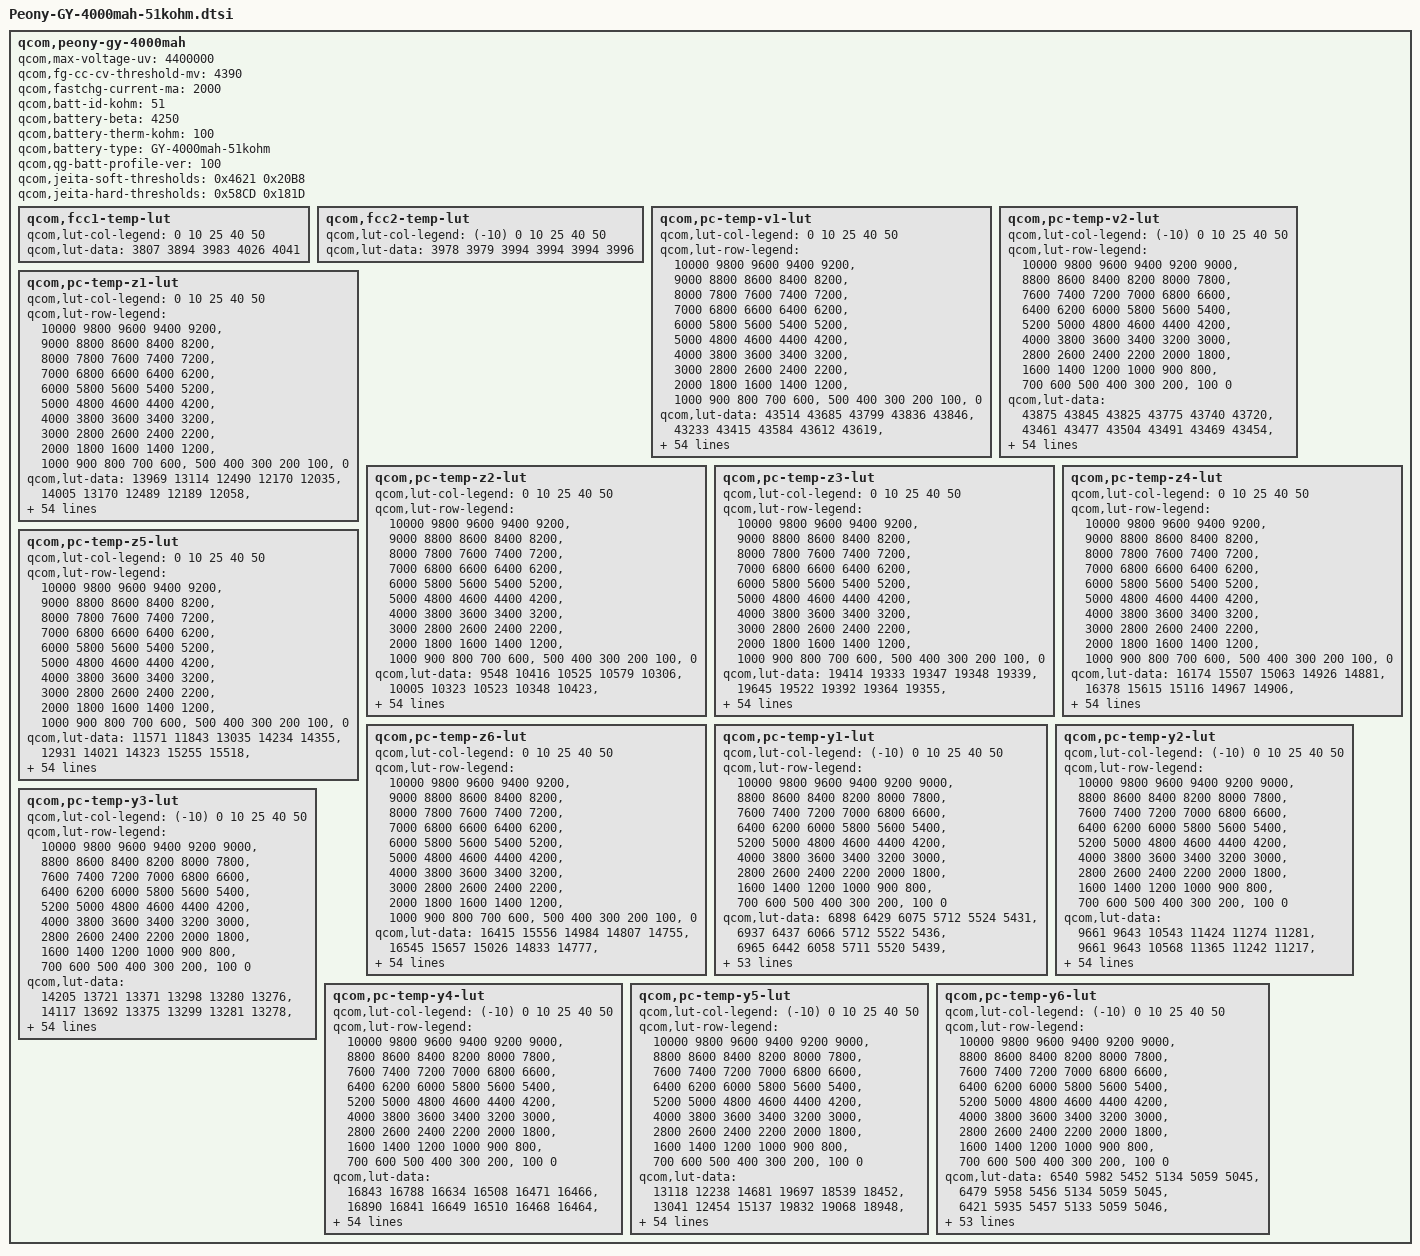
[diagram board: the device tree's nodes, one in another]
/* Copyright (c) 2018, The Linux Foundation. All rights reserved.
 * Copyright (C) 2021 XiaoMi, Inc.
 *
 * This program is free software; you can redistribute it and/or modify
 * it under the terms of the GNU General Public License version 2 and
 * only version 2 as published by the Free Software Foundation.
 *
 * This program is distributed in the hope that it will be useful,
 * but WITHOUT ANY WARRANTY; without even the implied warranty of
 * MERCHANTABILITY or FITNESS FOR A PARTICULAR PURPOSE.  See the
 * GNU General Public License for more details.
 */

qcom,peony-gy-4000mah {
	/* Peony-GY-4000mah-51kohm_Master_2018.12.27 */
	qcom,max-voltage-uv = <4400000>;
	qcom,fg-cc-cv-threshold-mv = <4390>;
	qcom,fastchg-current-ma = <2000>;
	qcom,batt-id-kohm = <51>;
	qcom,battery-beta = <4250>;
	qcom,battery-therm-kohm = <100>;
	qcom,battery-type =
		"GY-4000mah-51kohm";
	qcom,qg-batt-profile-ver = <100>;

/*	qcom,jeita-fcc-ranges = <0   50   400000
				 51  100  1200000
				 101 150  1950000
				 151 450  2000000
				 451 550  1000000
				 551 600  0>;
	qcom,jeita-fv-ranges =  <0   50   4400000
				 51  100  4400000
				 101 150  4400000
				 151 450  4400000
				 451 550  4100000
				 551 600  4100000>;*/

	/* COOL = 15 DegC, WARM = 45 DegC */
	qcom,jeita-soft-thresholds = <0x4621 0x20B8>;
	/* COLD = 0 DegC, HOT = 55 DegC */
	qcom,jeita-hard-thresholds = <0x58CD 0x181D>;

	qcom,fcc1-temp-lut {
		qcom,lut-col-legend = <0 10 25 40 50>;
		qcom,lut-data = <3807 3894 3983 4026 4041>;
	};

	qcom,fcc2-temp-lut {
		qcom,lut-col-legend = <(-10) 0 10 25 40 50>;
		qcom,lut-data = <3978 3979 3994 3994 3994 3996>;
	};

	qcom,pc-temp-v1-lut {
		qcom,lut-col-legend = <0 10 25 40 50>;
		qcom,lut-row-legend = <10000 9800 9600 9400 9200>,
			<9000 8800 8600 8400 8200>,
			<8000 7800 7600 7400 7200>,
			<7000 6800 6600 6400 6200>,
			<6000 5800 5600 5400 5200>,
			<5000 4800 4600 4400 4200>,
			<4000 3800 3600 3400 3200>,
			<3000 2800 2600 2400 2200>,
			<2000 1800 1600 1400 1200>,
			<1000 900 800 700 600>,
			<500 400 300 200 100>,
			<0>;
		qcom,lut-data = <43514 43685 43799 43836 43846>,
			<43233 43415 43584 43612 43619>,
			<42976 43161 43332 43381 43391>,
			<42734 42918 43090 43147 43163>,
			<42501 42681 42854 42912 42930>,
			<42277 42447 42616 42675 42695>,
			<42060 42219 42376 42440 42462>,
			<41851 41999 42138 42206 42229>,
			<41649 41786 41909 41975 41998>,
			<41457 41578 41685 41746 41768>,
			<41269 41379 41467 41519 41540>,
			<41072 41186 41258 41299 41317>,
			<40859 40986 41056 41083 41096>,
			<40631 40779 40856 40875 40884>,
			<40375 40558 40650 40670 40680>,
			<40104 40305 40440 40472 40484>,
			<39898 40050 40223 40280 40294>,
			<39765 39873 40022 40096 40111>,
			<39656 39757 39862 39922 39935>,
			<39542 39649 39733 39766 39776>,
			<39428 39520 39579 39601 39611>,
			<39314 39377 39353 39375 39398>,
			<39197 39218 39108 39108 39138>,
			<39079 39017 38920 38915 38936>,
			<38965 38819 38764 38785 38801>,
			<38853 38679 38644 38676 38689>,
			<38746 38567 38555 38573 38581>,
			<38645 38480 38483 38481 38482>,
			<38548 38412 38413 38395 38390>,
			<38465 38356 38347 38314 38299>,
			<38403 38309 38287 38241 38217>,
			<38351 38268 38230 38173 38148>,
			<38305 38232 38178 38112 38087>,
			<38262 38201 38131 38055 38028>,
			<38224 38174 38091 38006 37973>,
			<38190 38142 38050 37958 37918>,
			<38160 38109 38008 37908 37862>,
			<38123 38067 37961 37857 37804>,
			<38072 38003 37895 37790 37731>,
			<38004 37913 37804 37700 37635>,
			<37916 37812 37700 37597 37527>,
			<37794 37694 37589 37486 37415>,
			<37658 37559 37461 37359 37290>,
			<37504 37395 37301 37204 37130>,
			<37354 37265 37165 37072 37003>,
			<37249 37191 37080 36985 36926>,
			<37212 37154 37050 36959 36901>,
			<37180 37126 37035 36941 36881>,
			<37147 37099 37013 36919 36858>,
			<37076 37035 36948 36839 36768>,
			<36834 36772 36679 36544 36449>,
			<36384 36325 36241 36097 36002>,
			<35810 35750 35668 35517 35421>,
			<35030 34967 34890 34727 34627>,
			<33792 33731 33678 33490 33384>,
			<30000 30000 30000 30000 30000>;
	};

	qcom,pc-temp-v2-lut {
		qcom,lut-col-legend = <(-10) 0 10 25 40 50>;
		qcom,lut-row-legend = <10000 9800 9600 9400 9200 9000>,
			<8800 8600 8400 8200 8000 7800>,
			<7600 7400 7200 7000 6800 6600>,
			<6400 6200 6000 5800 5600 5400>,
			<5200 5000 4800 4600 4400 4200>,
			<4000 3800 3600 3400 3200 3000>,
			<2800 2600 2400 2200 2000 1800>,
			<1600 1400 1200 1000 900 800>,
			<700 600 500 400 300 200>,
			<100 0>;
		qcom,lut-data = <43875 43845 43825 43775 43740 43720>,
			<43461 43477 43504 43491 43469 43454>,
			<43087 43138 43205 43222 43207 43197>,
			<42758 42832 42929 42965 42957 42951>,
			<42469 42555 42676 42723 42719 42715>,
			<42203 42301 42431 42485 42484 42482>,
			<41947 42072 42183 42249 42249 42248>,
			<41710 41855 41941 42015 42016 42015>,
			<41492 41616 41716 41788 41786 41785>,
			<41283 41336 41505 41564 41559 41558>,
			<41114 41129 41301 41346 41336 41334>,
			<41015 41046 41111 41133 41118 41114>,
			<40930 40986 40922 40926 40903 40899>,
			<40726 40820 40702 40720 40696 40692>,
			<40165 40343 40443 40508 40494 40490>,
			<39661 39893 40190 40300 40299 40295>,
			<39455 39667 39961 40095 40113 40109>,
			<39309 39493 39742 39902 39933 39929>,
			<39149 39313 39537 39728 39760 39756>,
			<38974 39130 39346 39566 39595 39593>,
			<38810 38955 39162 39387 39417 39417>,
			<38661 38788 38972 39161 39187 39189>,
			<38526 38630 38789 38927 38944 38949>,
			<38415 38489 38633 38749 38761 38766>,
			<38325 38361 38497 38607 38620 38623>,
			<38245 38254 38372 38484 38497 38499>,
			<38173 38175 38250 38375 38387 38387>,
			<38108 38111 38139 38277 38288 38287>,
			<38048 38055 38057 38187 38199 38196>,
			<37993 38005 37995 38105 38118 38112>,
			<37939 37960 37943 38030 38045 38038>,
			<37885 37916 37897 37959 37979 37972>,
			<37832 37873 37856 37894 37919 37911>,
			<37776 37830 37815 37834 37852 37841>,
			<37720 37787 37776 37780 37779 37763>,
			<37661 37742 37734 37725 37699 37675>,
			<37597 37692 37688 37665 37609 37571>,
			<37530 37637 37636 37602 37515 37459>,
			<37464 37573 37575 37533 37431 37368>,
			<37401 37500 37503 37459 37357 37293>,
			<37338 37416 37421 37377 37280 37215>,
			<37274 37318 37323 37280 37185 37122>,
			<37208 37207 37209 37166 37075 37016>,
			<37135 37098 37083 37041 36951 36893>,
			<37052 37002 36959 36927 36854 36797>,
			<36947 36919 36872 36870 36808 36755>,
			<36885 36879 36837 36852 36795 36742>,
			<36806 36833 36805 36831 36776 36723>,
			<36705 36770 36759 36789 36734 36677>,
			<36550 36655 36646 36671 36589 36511>,
			<36309 36402 36381 36342 36215 36119>,
			<35914 35962 35915 35839 35693 35595>,
			<35338 35342 35275 35180 35017 34909>,
			<34487 34468 34383 34260 34073 33958>,
			<33097 33083 33023 32941 32737 32624>,
			<28238 27945 27843 28406 27873 27872>;
	};

	qcom,pc-temp-z1-lut {
		qcom,lut-col-legend = <0 10 25 40 50>;
		qcom,lut-row-legend = <10000 9800 9600 9400 9200>,
			<9000 8800 8600 8400 8200>,
			<8000 7800 7600 7400 7200>,
			<7000 6800 6600 6400 6200>,
			<6000 5800 5600 5400 5200>,
			<5000 4800 4600 4400 4200>,
			<4000 3800 3600 3400 3200>,
			<3000 2800 2600 2400 2200>,
			<2000 1800 1600 1400 1200>,
			<1000 900 800 700 600>,
			<500 400 300 200 100>,
			<0>;
		qcom,lut-data = <13969 13114 12490 12170 12035>,
			<14005 13170 12489 12189 12058>,
			<14014 13164 12500 12193 12066>,
			<14005 13147 12505 12192 12068>,
			<13985 13138 12508 12187 12066>,
			<13962 13137 12508 12180 12062>,
			<13943 13140 12502 12173 12060>,
			<13927 13142 12490 12165 12059>,
			<13921 13137 12484 12162 12058>,
			<13925 13129 12478 12164 12060>,
			<13929 13126 12477 12166 12063>,
			<13921 13121 12481 12168 12065>,
			<13899 13109 12484 12170 12066>,
			<13872 13080 12479 12170 12067>,
			<13837 13063 12463 12168 12068>,
			<13788 13060 12453 12167 12069>,
			<13757 13053 12453 12168 12071>,
			<13748 13049 12454 12170 12073>,
			<13745 13055 12459 12171 12075>,
			<13747 13065 12472 12174 12078>,
			<13752 13076 12481 12177 12081>,
			<13759 13090 12486 12179 12082>,
			<13767 13101 12491 12180 12083>,
			<13777 13110 12494 12181 12084>,
			<13784 13118 12497 12184 12087>,
			<13781 13118 12500 12187 12091>,
			<13773 13111 12505 12191 12094>,
			<13770 13107 12510 12196 12097>,
			<13770 13128 12513 12200 12101>,
			<13773 13154 12515 12204 12104>,
			<13796 13160 12517 12209 12109>,
			<13824 13157 12519 12215 12113>,
			<13831 13156 12522 12220 12118>,
			<13834 13169 12525 12226 12123>,
			<13840 13194 12531 12232 12128>,
			<13845 13206 12538 12238 12133>,
			<13854 13211 12547 12242 12138>,
			<13866 13214 12557 12246 12142>,
			<13894 13214 12568 12250 12146>,
			<13930 13213 12583 12254 12150>,
			<13947 13215 12593 12259 12154>,
			<13957 13238 12594 12268 12158>,
			<13957 13248 12592 12275 12162>,
			<13939 13242 12593 12275 12165>,
			<13939 13275 12611 12277 12168>,
			<13913 13273 12605 12288 12170>,
			<13906 13292 12610 12284 12171>,
			<13933 13270 12604 12289 12175>,
			<13964 13266 12601 12292 12179>,
			<13981 13267 12617 12300 12185>,
			<13972 13272 12626 12307 12192>,
			<13958 13311 12637 12320 12201>,
			<13966 13310 12665 12330 12214>,
			<13998 13369 12691 12349 12232>,
			<13998 13369 12691 12349 12232>,
			<13998 13369 12691 12349 12232>;
	};

	qcom,pc-temp-z2-lut {
		qcom,lut-col-legend = <0 10 25 40 50>;
		qcom,lut-row-legend = <10000 9800 9600 9400 9200>,
			<9000 8800 8600 8400 8200>,
			<8000 7800 7600 7400 7200>,
			<7000 6800 6600 6400 6200>,
			<6000 5800 5600 5400 5200>,
			<5000 4800 4600 4400 4200>,
			<4000 3800 3600 3400 3200>,
			<3000 2800 2600 2400 2200>,
			<2000 1800 1600 1400 1200>,
			<1000 900 800 700 600>,
			<500 400 300 200 100>,
			<0>;
		qcom,lut-data = <9548 10416 10525 10579 10306>,
			<10005 10323 10523 10348 10423>,
			<10156 10349 10543 10486 10486>,
			<10211 10352 10710 10558 10522>,
			<10228 10345 11014 10545 10498>,
			<10237 10319 11062 10519 10457>,
			<10240 10291 10740 10483 10429>,
			<10241 10276 10451 10428 10391>,
			<10239 10262 10414 10399 10366>,
			<10226 10252 10393 10394 10363>,
			<10202 10246 10385 10396 10365>,
			<10179 10242 10391 10394 10370>,
			<10157 10273 10404 10385 10384>,
			<10138 10385 10489 10382 10388>,
			<10122 10450 10692 10399 10341>,
			<10107 10384 10831 10418 10283>,
			<10098 10289 10908 10409 10281>,
			<10094 10281 10946 10379 10303>,
			<10092 10311 10850 10368 10329>,
			<10093 10345 10615 10397 10352>,
			<10106 10370 10541 10447 10382>,
			<10119 10392 10602 10541 10463>,
			<10120 10408 10667 10685 10628>,
			<10120 10421 10669 10721 10697>,
			<10121 10429 10625 10574 10609>,
			<10129 10433 10594 10438 10507>,
			<10141 10441 10599 10465 10516>,
			<10154 10449 10612 10544 10583>,
			<10171 10462 10614 10582 10615>,
			<10187 10474 10609 10598 10624>,
			<10201 10480 10606 10606 10614>,
			<10214 10483 10615 10596 10557>,
			<10229 10488 10628 10573 10473>,
			<10247 10495 10632 10559 10411>,
			<10262 10506 10634 10551 10362>,
			<10243 10518 10636 10547 10334>,
			<10141 10532 10650 10577 10361>,
			<10072 10549 10674 10639 10431>,
			<9992 10572 10705 10663 10485>,
			<9920 10599 10751 10670 10529>,
			<9931 10617 10774 10675 10555>,
			<9974 10625 10764 10699 10554>,
			<10016 10634 10754 10727 10553>,
			<10057 10651 10765 10701 10638>,
			<10194 10758 10817 10686 10622>,
			<10329 14680 10837 10625 10523>,
			<10361 15143 10842 10651 10529>,
			<10255 14898 10814 10642 10542>,
			<10229 15989 10836 10711 10586>,
			<10228 21524 10894 10782 10715>,
			<10052 14520 10903 10658 10433>,
			<9856 14190 10874 10463 10283>,
			<9735 13311 10767 10402 10217>,
			<9567 12542 10654 10309 10162>,
			<9567 12542 10654 10309 10162>,
			<9567 12542 10654 10309 10162>;
	};

	qcom,pc-temp-z3-lut {
		qcom,lut-col-legend = <0 10 25 40 50>;
		qcom,lut-row-legend = <10000 9800 9600 9400 9200>,
			<9000 8800 8600 8400 8200>,
			<8000 7800 7600 7400 7200>,
			<7000 6800 6600 6400 6200>,
			<6000 5800 5600 5400 5200>,
			<5000 4800 4600 4400 4200>,
			<4000 3800 3600 3400 3200>,
			<3000 2800 2600 2400 2200>,
			<2000 1800 1600 1400 1200>,
			<1000 900 800 700 600>,
			<500 400 300 200 100>,
			<0>;
		qcom,lut-data = <19414 19333 19347 19348 19339>,
			<19645 19522 19392 19364 19355>,
			<19720 19571 19441 19389 19374>,
			<19736 19596 19459 19403 19388>,
			<19728 19605 19467 19411 19396>,
			<19715 19607 19471 19416 19402>,
			<19705 19606 19474 19417 19404>,
			<19695 19603 19476 19417 19404>,
			<19688 19596 19476 19416 19404>,
			<19683 19589 19474 19413 19402>,
			<19680 19584 19470 19408 19398>,
			<19680 19581 19463 19403 19395>,
			<19687 19579 19455 19395 19392>,
			<19695 19577 19454 19390 19388>,
			<19701 19574 19454 19387 19381>,
			<19706 19564 19454 19384 19372>,
			<19707 19548 19451 19381 19368>,
			<19684 19533 19446 19378 19365>,
			<19648 19509 19436 19374 19362>,
			<19625 19488 19417 19368 19355>,
			<19609 19488 19410 19364 19349>,
			<19600 19496 19419 19368 19350>,
			<19604 19503 19430 19378 19358>,
			<19617 19515 19431 19381 19361>,
			<19627 19526 19425 19367 19349>,
			<19634 19526 19420 19355 19336>,
			<19639 19525 19417 19355 19339>,
			<19640 19524 19416 19359 19351>,
			<19640 19523 19416 19363 19364>,
			<19639 19520 19418 19374 19381>,
			<19633 19518 19419 19383 19393>,
			<19621 19514 19422 19386 19390>,
			<19610 19509 19425 19389 19382>,
			<19600 19504 19425 19389 19374>,
			<19588 19497 19423 19383 19366>,
			<19552 19491 19420 19377 19358>,
			<19465 19484 19416 19372 19352>,
			<19406 19479 19412 19367 19347>,
			<19344 19478 19410 19364 19346>,
			<19276 19477 19408 19361 19345>,
			<19265 19476 19405 19359 19346>,
			<19264 19470 19401 19359 19346>,
			<19263 19465 19398 19358 19348>,
			<19262 19462 19398 19359 19357>,
			<19261 19386 19391 19355 19355>,
			<19260 19259 19375 19348 19342>,
			<19260 19259 19378 19344 19334>,
			<19260 19259 19360 19337 19329>,
			<19261 19258 19351 19334 19321>,
			<19261 19256 19346 19330 19316>,
			<19261 19258 19342 19343 19351>,
			<19263 19258 19345 19357 19354>,
			<19264 19259 19352 19360 19355>,
			<19268 19259 19345 19358 19355>,
			<19268 19259 19345 19358 19355>,
			<19268 19259 19345 19358 19355>;
	};

	qcom,pc-temp-z4-lut {
		qcom,lut-col-legend = <0 10 25 40 50>;
		qcom,lut-row-legend = <10000 9800 9600 9400 9200>,
			<9000 8800 8600 8400 8200>,
			<8000 7800 7600 7400 7200>,
			<7000 6800 6600 6400 6200>,
			<6000 5800 5600 5400 5200>,
			<5000 4800 4600 4400 4200>,
			<4000 3800 3600 3400 3200>,
			<3000 2800 2600 2400 2200>,
			<2000 1800 1600 1400 1200>,
			<1000 900 800 700 600>,
			<500 400 300 200 100>,
			<0>;
		qcom,lut-data = <16174 15507 15063 14926 14881>,
			<16378 15615 15116 14967 14906>,
			<16245 15555 15100 14938 14889>,
			<16076 15373 15052 14905 14867>,
			<15884 15216 14959 14870 14842>,
			<15699 15117 14894 14835 14814>,
			<15559 15035 14857 14807 14791>,
			<15443 14971 14827 14784 14770>,
			<15346 14918 14797 14763 14753>,
			<15264 14876 14770 14744 14737>,
			<15192 14845 14752 14728 14723>,
			<15122 14817 14741 14722 14714>,
			<15052 14782 14731 14718 14708>,
			<15000 14739 14715 14713 14703>,
			<14975 14718 14694 14705 14700>,
			<14958 14733 14685 14698 14697>,
			<14939 14754 14681 14690 14693>,
			<14911 14757 14678 14683 14686>,
			<14882 14743 14675 14679 14681>,
			<14861 14729 14674 14676 14678>,
			<14846 14718 14678 14674 14676>,
			<14831 14707 14718 14704 14698>,
			<14811 14705 14776 14781 14770>,
			<14787 14742 14812 14816 14811>,
			<14771 14790 14838 14827 14821>,
			<14761 14805 14848 14832 14827>,
			<14755 14812 14836 14825 14818>,
			<14755 14814 14815 14804 14788>,
			<14758 14803 14796 14782 14759>,
			<14760 14786 14778 14757 14728>,
			<14758 14771 14761 14734 14705>,
			<14753 14756 14746 14716 14695>,
			<14749 14742 14733 14702 14689>,
			<14745 14729 14722 14696 14687>,
			<14741 14716 14712 14693 14686>,
			<14760 14707 14705 14691 14686>,
			<14836 14698 14701 14690 14686>,
			<14883 14693 14698 14690 14687>,
			<14938 14693 14699 14691 14689>,
			<15000 14692 14705 14701 14701>,
			<15005 14692 14708 14709 14710>,
			<14999 14691 14702 14703 14704>,
			<14991 14690 14695 14695 14695>,
			<14977 14687 14693 14695 14693>,
			<14910 14732 14678 14686 14684>,
			<14896 14835 14664 14667 14668>,
			<14889 14828 14652 14661 14664>,
			<14883 14822 14655 14649 14650>,
			<14876 14814 14653 14633 14636>,
			<14873 14811 14656 14637 14638>,
			<14881 14825 14684 14659 14650>,
			<14903 14841 14690 14655 14657>,
			<14917 14851 14688 14656 14661>,
			<14942 14865 14702 14664 14665>,
			<14942 14865 14702 14664 14665>,
			<14942 14865 14702 14664 14665>;
	};

	qcom,pc-temp-z5-lut {
		qcom,lut-col-legend = <0 10 25 40 50>;
		qcom,lut-row-legend = <10000 9800 9600 9400 9200>,
			<9000 8800 8600 8400 8200>,
			<8000 7800 7600 7400 7200>,
			<7000 6800 6600 6400 6200>,
			<6000 5800 5600 5400 5200>,
			<5000 4800 4600 4400 4200>,
			<4000 3800 3600 3400 3200>,
			<3000 2800 2600 2400 2200>,
			<2000 1800 1600 1400 1200>,
			<1000 900 800 700 600>,
			<500 400 300 200 100>,
			<0>;
		qcom,lut-data = <11571 11843 13035 14234 14355>,
			<12931 14021 14323 15255 15518>,
			<13612 15060 15919 16720 16930>,
			<14055 15749 16679 17786 18097>,
			<14381 16360 17143 18420 18880>,
			<14654 16910 17722 18944 19566>,
			<14936 17426 18846 19475 20211>,
			<15211 17967 20115 19976 20785>,
			<15491 18506 21199 20555 21401>,
			<15784 19149 22324 21524 22170>,
			<16119 20008 23283 22315 23059>,
			<16572 21163 23941 22291 24064>,
			<17248 23019 24668 21987 25269>,
			<18049 26039 26037 21874 25785>,
			<18958 27678 28941 22510 25056>,
			<20004 26882 31254 23503 24120>,
			<20467 25411 31654 24370 24402>,
			<19602 24500 30952 25283 25950>,
			<18245 22772 30110 26186 26923>,
			<17760 21243 29586 26989 26802>,
			<17655 22762 31061 28001 26431>,
			<17656 28695 39345 30446 26852>,
			<18498 35086 48510 34201 28650>,
			<20943 44649 47721 34841 29300>,
			<23732 52317 38698 27375 23766>,
			<26823 51972 31398 20057 17658>,
			<30047 48304 28196 18963 17170>,
			<33216 45025 26176 18473 17565>,
			<36728 42990 25852 18484 18455>,
			<38541 41332 26010 19954 22572>,
			<37615 40323 26423 22241 26812>,
			<35372 39431 28357 25359 28120>,
			<33282 38553 31470 29332 28908>,
			<31524 37490 34049 31774 29301>,
			<29583 36279 36504 33446 29383>,
			<26391 35429 38242 34270 29209>,
			<21145 34750 39361 34165 28866>,
			<17664 34388 40098 33798 28412>,
			<14699 35993 39974 33005 27733>,
			<11754 39483 38639 30407 26369>,
			<11342 40387 36783 27763 25089>,
			<11366 36415 33498 26033 24318>,
			<11389 34436 31186 24989 23870>,
			<11422 35750 31549 24944 27112>,
			<11717 26547 31969 24900 27387>,
			<11686 11837 27956 24072 22607>,
			<11638 11801 31341 23310 20529>,
			<11639 11786 23238 22816 21399>,
			<11638 11698 21003 26062 22631>,
			<11662 11719 19921 23230 20023>,
			<11715 11851 17379 20703 25333>,
			<11695 11735 16567 22350 22802>,
			<11591 11628 16970 21885 20933>,
			<11484 11502 15329 19253 18815>,
			<11484 11502 15329 19253 18815>,
			<11484 11502 15329 19253 18815>;
	};

	qcom,pc-temp-z6-lut {
		qcom,lut-col-legend = <0 10 25 40 50>;
		qcom,lut-row-legend = <10000 9800 9600 9400 9200>,
			<9000 8800 8600 8400 8200>,
			<8000 7800 7600 7400 7200>,
			<7000 6800 6600 6400 6200>,
			<6000 5800 5600 5400 5200>,
			<5000 4800 4600 4400 4200>,
			<4000 3800 3600 3400 3200>,
			<3000 2800 2600 2400 2200>,
			<2000 1800 1600 1400 1200>,
			<1000 900 800 700 600>,
			<500 400 300 200 100>,
			<0>;
		qcom,lut-data = <16415 15556 14984 14807 14755>,
			<16545 15657 15026 14833 14777>,
			<16471 15628 15034 14832 14780>,
			<16372 15535 15021 14827 14778>,
			<16244 15449 14981 14815 14772>,
			<16117 15387 14947 14800 14763>,
			<16021 15333 14927 14789 14755>,
			<15941 15288 14910 14778 14747>,
			<15873 15249 14894 14768 14739>,
			<15816 15217 14878 14758 14731>,
			<15765 15193 14867 14749 14723>,
			<15712 15172 14858 14742 14718>,
			<15655 15144 14851 14737 14713>,
			<15606 15109 14840 14731 14709>,
			<15574 15086 14827 14726 14703>,
			<15549 15081 14820 14721 14698>,
			<15523 15078 14817 14716 14693>,
			<15490 15072 14813 14711 14689>,
			<15458 15058 14808 14707 14685>,
			<15436 15046 14801 14703 14680>,
			<15420 15046 14798 14700 14676>,
			<15412 15049 14820 14716 14687>,
			<15412 15055 14854 14756 14724>,
			<15413 15079 14869 14770 14740>,
			<15415 15107 14879 14768 14739>,
			<15419 15116 14882 14766 14737>,
			<15424 15121 14877 14763 14734>,
			<15429 15122 14869 14757 14729>,
			<15434 15119 14862 14752 14725>,
			<15436 15114 14856 14747 14721>,
			<15434 15109 14852 14743 14718>,
			<15429 15103 14849 14739 14713>,
			<15426 15098 14846 14736 14708>,
			<15424 15091 14842 14733 14703>,
			<15423 15085 14839 14729 14699>,
			<15419 15083 14836 14726 14695>,
			<15413 15082 14835 14724 14692>,
			<15410 15081 14834 14721 14690>,
			<15411 15083 14835 14721 14690>,
			<15413 15089 14839 14725 14695>,
			<15417 15093 14842 14728 14700>,
			<15424 15096 14840 14726 14698>,
			<15430 15099 14837 14724 14696>,
			<15437 15107 14840 14725 14700>,
			<15428 15097 14835 14720 14696>,
			<15421 15084 14823 14709 14682>,
			<15420 15082 14820 14704 14677>,
			<15418 15081 14813 14696 14669>,
			<15417 15080 14809 14689 14658>,
			<15422 15084 14811 14690 14658>,
			<15436 15098 14826 14708 14683>,
			<15456 15115 14835 14716 14691>,
			<15479 15133 14844 14722 14696>,
			<15520 15159 14857 14730 14703>,
			<15520 15159 14857 14730 14703>,
			<15520 15159 14857 14730 14703>;
	};

	qcom,pc-temp-y1-lut {
		qcom,lut-col-legend = <(-10) 0 10 25 40 50>;
		qcom,lut-row-legend = <10000 9800 9600 9400 9200 9000>,
			<8800 8600 8400 8200 8000 7800>,
			<7600 7400 7200 7000 6800 6600>,
			<6400 6200 6000 5800 5600 5400>,
			<5200 5000 4800 4600 4400 4200>,
			<4000 3800 3600 3400 3200 3000>,
			<2800 2600 2400 2200 2000 1800>,
			<1600 1400 1200 1000 900 800>,
			<700 600 500 400 300 200>,
			<100 0>;
		qcom,lut-data = <6898 6429 6075 5712 5524 5431>,
			<6937 6437 6066 5712 5522 5436>,
			<6965 6442 6058 5711 5520 5439>,
			<6983 6443 6050 5711 5517 5442>,
			<6992 6443 6045 5710 5515 5443>,
			<6991 6440 6044 5710 5513 5443>,
			<6973 6432 6045 5708 5513 5442>,
			<6949 6423 6048 5706 5513 5440>,
			<6947 6423 6048 5703 5512 5439>,
			<6962 6440 6044 5698 5510 5437>,
			<6973 6453 6041 5694 5507 5436>,
			<6972 6452 6047 5696 5506 5436>,
			<6972 6448 6058 5698 5505 5436>,
			<6977 6447 6060 5699 5505 5436>,
			<6984 6447 6061 5698 5505 5436>,
			<6990 6448 6062 5698 5505 5436>,
			<6996 6459 6071 5705 5506 5437>,
			<7004 6475 6082 5714 5507 5437>,
			<7006 6478 6083 5715 5508 5438>,
			<7005 6473 6080 5709 5508 5439>,
			<7004 6467 6077 5706 5508 5440>,
			<6996 6467 6076 5707 5509 5441>,
			<6983 6468 6076 5710 5511 5442>,
			<6980 6468 6077 5711 5512 5443>,
			<6991 6469 6080 5711 5513 5445>,
			<7002 6470 6081 5710 5515 5447>,
			<7002 6465 6080 5710 5517 5449>,
			<7002 6459 6078 5714 5519 5451>,
			<6999 6458 6076 5716 5522 5453>,
			<6983 6452 6070 5718 5525 5456>,
			<6967 6447 6066 5720 5529 5459>,
			<6970 6452 6068 5726 5533 5461>,
			<6981 6462 6072 5731 5537 5464>,
			<6986 6464 6075 5731 5539 5467>,
			<6989 6454 6080 5729 5541 5468>,
			<6988 6447 6083 5729 5542 5470>,
			<6980 6447 6078 5732 5544 5472>,
			<6968 6449 6071 5734 5546 5474>,
			<6965 6452 6071 5734 5547 5476>,
			<6970 6465 6078 5734 5548 5478>,
			<6978 6474 6085 5735 5549 5480>,
			<6992 6475 6090 5746 5552 5482>,
			<7005 6481 6092 5754 5556 5484>,
			<7008 6489 6088 5755 5559 5487>,
			<7015 6482 6099 5752 5565 5492>,
			<7049 6495 6103 5772 5574 5495>,
			<7053 6534 6117 5768 5571 5494>,
			<7094 6532 6133 5767 5571 5494>,
			<7080 6539 6134 5761 5573 5495>,
			<7076 6545 6132 5765 5570 5496>,
			<7131 6545 6131 5772 5576 5501>,
			<7144 6556 6171 5782 5587 5509>,
			<7172 6623 6187 5811 5599 5519>,
			<7260 6610 6216 5838 5618 5532>,
			<7260 6610 6216 5838 5618 5532>,
			<7260 6610 6216 5838 5618 5532>;
	};

	qcom,pc-temp-y2-lut {
		qcom,lut-col-legend = <(-10) 0 10 25 40 50>;
		qcom,lut-row-legend = <10000 9800 9600 9400 9200 9000>,
			<8800 8600 8400 8200 8000 7800>,
			<7600 7400 7200 7000 6800 6600>,
			<6400 6200 6000 5800 5600 5400>,
			<5200 5000 4800 4600 4400 4200>,
			<4000 3800 3600 3400 3200 3000>,
			<2800 2600 2400 2200 2000 1800>,
			<1600 1400 1200 1000 900 800>,
			<700 600 500 400 300 200>,
			<100 0>;
		qcom,lut-data = <9661 9643 10543 11424 11274 11281>,
			<9661 9643 10568 11365 11242 11217>,
			<9662 9643 10592 11307 11209 11154>,
			<9662 9746 10616 11254 11174 11094>,
			<9663 9858 10640 11206 11138 11042>,
			<9664 9913 10663 11165 11102 11003>,
			<9666 10002 10690 11129 11060 10972>,
			<9667 10137 10714 11100 11020 10948>,
			<9668 10167 10704 11080 10994 10936>,
			<9668 10202 10626 11067 10976 10930>,
			<9668 10238 10575 11056 10963 10925>,
			<9668 10194 10778 11046 10972 10909>,
			<9669 10110 11102 11038 10997 10887>,
			<9669 10099 11149 11049 11007 10881>,
			<9668 10187 11040 11133 11026 10906>,
			<9667 10257 10965 11222 11049 10935>,
			<9667 10105 11021 11276 11092 10971>,
			<9667 9797 11116 11326 11170 11028>,
			<9667 9698 11157 11388 11274 11114>,
			<9667 9691 11181 11470 11436 11294>,
			<9667 9688 11194 11509 11527 11404>,
			<9666 9686 11198 11474 11488 11363>,
			<9666 9685 11203 11429 11408 11285>,
			<9666 9685 11204 11425 11359 11262>,
			<9666 9686 11202 11440 11320 11258>,
			<9666 9687 11194 11454 11301 11260>,
			<9665 9686 10978 11461 11326 11276>,
			<9665 9683 10673 11467 11375 11307>,
			<9665 9681 10571 11485 11414 11340>,
			<9664 9678 10296 11523 11453 11383>,
			<9664 9675 10075 11544 11498 11433>,
			<9664 9673 10157 11553 11565 11517>,
			<9663 9672 10358 11560 11630 11605>,
			<9663 9670 10384 11560 11640 11608>,
			<9663 9668 10104 11548 11614 11532>,
			<9663 9667 9837 11531 11577 11454>,
			<9662 9666 9761 11500 11500 11395>,
			<9662 9665 9715 11455 11411 11336>,
			<9662 9664 9697 11418 11398 11287>,
			<9661 9663 9690 11386 11419 11241>,
			<9661 9662 9684 11349 11433 11220>,
			<9661 9661 9678 11302 11423 11258>,
			<9661 9661 9673 11253 11395 11304>,
			<9661 9660 9669 11181 11308 11210>,
			<9660 9660 9665 11068 11182 11020>,
			<9659 9659 9664 11026 11128 10952>,
			<9659 9659 9663 11026 11170 10986>,
			<9659 9659 9662 11026 11160 11042>,
			<9659 9658 9660 11029 11192 11053>,
			<9659 9658 9659 11015 11184 11030>,
			<9658 9658 9658 10939 11102 10900>,
			<9658 9657 9658 10821 11009 10810>,
			<9657 9657 9657 10707 10919 10725>,
			<9654 9656 9656 10612 10844 10644>,
			<9654 9656 9656 10612 10844 10644>,
			<9654 9656 9656 10612 10844 10644>;
	};

	qcom,pc-temp-y3-lut {
		qcom,lut-col-legend = <(-10) 0 10 25 40 50>;
		qcom,lut-row-legend = <10000 9800 9600 9400 9200 9000>,
			<8800 8600 8400 8200 8000 7800>,
			<7600 7400 7200 7000 6800 6600>,
			<6400 6200 6000 5800 5600 5400>,
			<5200 5000 4800 4600 4400 4200>,
			<4000 3800 3600 3400 3200 3000>,
			<2800 2600 2400 2200 2000 1800>,
			<1600 1400 1200 1000 900 800>,
			<700 600 500 400 300 200>,
			<100 0>;
		qcom,lut-data = <14205 13721 13371 13298 13280 13276>,
			<14117 13692 13375 13299 13281 13278>,
			<14029 13659 13379 13300 13282 13279>,
			<13947 13623 13383 13301 13284 13280>,
			<13876 13591 13386 13303 13285 13281>,
			<13823 13567 13388 13304 13285 13282>,
			<13790 13550 13388 13305 13285 13283>,
			<13762 13533 13387 13306 13285 13284>,
			<13715 13515 13390 13307 13286 13284>,
			<13630 13496 13407 13309 13286 13284>,
			<13579 13479 13417 13310 13287 13285>,
			<13583 13456 13398 13312 13288 13285>,
			<13592 13425 13366 13313 13290 13286>,
			<13590 13418 13357 13314 13291 13287>,
			<13564 13422 13357 13315 13293 13288>,
			<13543 13425 13357 13315 13295 13290>,
			<13540 13418 13355 13312 13295 13290>,
			<13538 13406 13351 13308 13295 13291>,
			<13539 13397 13347 13307 13295 13291>,
			<13544 13388 13342 13307 13294 13291>,
			<13547 13379 13336 13306 13293 13291>,
			<13547 13372 13331 13303 13289 13288>,
			<13547 13365 13326 13298 13284 13282>,
			<13548 13357 13323 13295 13283 13280>,
			<13556 13345 13320 13294 13282 13280>,
			<13567 13338 13317 13293 13281 13279>,
			<13579 13341 13305 13293 13281 13279>,
			<13595 13350 13291 13292 13280 13278>,
			<13612 13361 13286 13293 13280 13277>,
			<13632 13376 13272 13293 13280 13277>,
			<13654 13392 13262 13292 13280 13277>,
			<13680 13409 13269 13292 13281 13277>,
			<13708 13428 13286 13292 13283 13279>,
			<13737 13449 13298 13292 13283 13279>,
			<13765 13473 13316 13292 13283 13280>,
			<13794 13500 13325 13293 13282 13280>,
			<13826 13529 13325 13293 13281 13279>,
			<13860 13559 13325 13293 13280 13278>,
			<13897 13593 13328 13293 13280 13278>,
			<13939 13632 13344 13294 13282 13280>,
			<13984 13673 13365 13295 13284 13282>,
			<14031 13717 13389 13296 13284 13282>,
			<14081 13762 13421 13298 13284 13283>,
			<14134 13811 13471 13299 13283 13281>,
			<14199 13870 13536 13299 13283 13282>,
			<14236 13904 13548 13303 13288 13287>,
			<14248 13919 13578 13306 13292 13289>,
			<14320 13971 13631 13311 13295 13291>,
			<14388 14018 13692 13316 13296 13291>,
			<14455 14066 13744 13319 13294 13289>,
			<14531 14113 13806 13316 13291 13287>,
			<14614 14167 13887 13320 13293 13288>,
			<14773 14254 14006 13329 13298 13294>,
			<15355 14380 14110 13346 13308 13301>,
			<15355 14380 14110 13346 13308 13301>,
			<15355 14380 14110 13346 13308 13301>;
	};

	qcom,pc-temp-y4-lut {
		qcom,lut-col-legend = <(-10) 0 10 25 40 50>;
		qcom,lut-row-legend = <10000 9800 9600 9400 9200 9000>,
			<8800 8600 8400 8200 8000 7800>,
			<7600 7400 7200 7000 6800 6600>,
			<6400 6200 6000 5800 5600 5400>,
			<5200 5000 4800 4600 4400 4200>,
			<4000 3800 3600 3400 3200 3000>,
			<2800 2600 2400 2200 2000 1800>,
			<1600 1400 1200 1000 900 800>,
			<700 600 500 400 300 200>,
			<100 0>;
		qcom,lut-data = <16843 16788 16634 16508 16471 16466>,
			<16890 16841 16649 16510 16468 16464>,
			<16941 16881 16677 16512 16466 16463>,
			<16988 16910 16709 16515 16465 16461>,
			<17022 16927 16735 16517 16465 16460>,
			<17035 16934 16746 16518 16465 16460>,
			<17026 16923 16745 16519 16467 16460>,
			<17011 16906 16744 16520 16471 16461>,
			<17028 16907 16741 16522 16474 16463>,
			<17155 16935 16730 16526 16478 16465>,
			<17279 16979 16724 16531 16481 16469>,
			<17353 17130 16805 16535 16484 16472>,
			<17412 17351 16931 16539 16488 16477>,
			<17374 17353 16947 16550 16492 16481>,
			<17038 17019 16900 16577 16499 16485>,
			<16784 16771 16861 16603 16508 16489>,
			<16783 16771 16821 16621 16520 16497>,
			<16787 16777 16760 16639 16535 16508>,
			<16783 16775 16728 16649 16554 16524>,
			<16746 16749 16706 16649 16581 16551>,
			<16710 16715 16682 16639 16595 16566>,
			<16693 16682 16646 16587 16559 16539>,
			<16681 16648 16605 16520 16497 16492>,
			<16675 16631 16578 16496 16474 16472>,
			<16673 16622 16559 16486 16465 16462>,
			<16672 16617 16547 16483 16462 16459>,
			<16672 16616 16543 16484 16464 16461>,
			<16673 16615 16542 16487 16470 16466>,
			<16673 16614 16548 16490 16477 16472>,
			<16673 16612 16579 16495 16485 16481>,
			<16674 16611 16602 16499 16494 16490>,
			<16675 16614 16591 16501 16504 16502>,
			<16679 16621 16567 16502 16513 16512>,
			<16682 16629 16560 16503 16514 16514>,
			<16685 16636 16568 16503 16509 16511>,
			<16689 16644 16581 16502 16502 16507>,
			<16696 16652 16598 16497 16487 16489>,
			<16704 16661 16618 16492 16470 16467>,
			<16715 16667 16629 16491 16466 16464>,
			<16727 16673 16636 16493 16470 16470>,
			<16743 16676 16643 16496 16474 16476>,
			<16765 16670 16650 16503 16477 16479>,
			<16795 16659 16655 16506 16476 16480>,
			<16832 16654 16651 16507 16465 16461>,
			<16854 16659 16647 16511 16463 16454>,
			<16820 16666 16636 16521 16473 16476>,
			<16805 16668 16646 16529 16495 16507>,
			<16797 16697 16674 16555 16528 16540>,
			<16809 16733 16718 16590 16556 16562>,
			<16817 16753 16738 16604 16542 16534>,
			<16817 16746 16734 16570 16485 16476>,
			<16811 16727 16712 16565 16482 16474>,
			<16833 16734 16714 16592 16496 16480>,
			<17045 16768 16744 16645 16541 16519>,
			<17045 16768 16744 16645 16541 16519>,
			<17045 16768 16744 16645 16541 16519>;
	};

	qcom,pc-temp-y5-lut {
		qcom,lut-col-legend = <(-10) 0 10 25 40 50>;
		qcom,lut-row-legend = <10000 9800 9600 9400 9200 9000>,
			<8800 8600 8400 8200 8000 7800>,
			<7600 7400 7200 7000 6800 6600>,
			<6400 6200 6000 5800 5600 5400>,
			<5200 5000 4800 4600 4400 4200>,
			<4000 3800 3600 3400 3200 3000>,
			<2800 2600 2400 2200 2000 1800>,
			<1600 1400 1200 1000 900 800>,
			<700 600 500 400 300 200>,
			<100 0>;
		qcom,lut-data = <13118 12238 14681 19697 18539 18452>,
			<13041 12454 15137 19832 19068 18948>,
			<13080 12885 15839 19842 19296 19321>,
			<13212 13455 16601 19751 19290 19552>,
			<13414 14091 17238 19587 19119 19621>,
			<13664 14718 17565 19372 18855 19510>,
			<14080 15993 17634 19012 18134 19169>,
			<14514 17501 17683 18561 17090 18712>,
			<14435 17386 18289 18250 16468 18265>,
			<13431 15074 21045 18014 16057 17500>,
			<12712 13493 22832 17742 15755 16835>,
			<15699 14698 19679 17160 15617 16341>,
			<20849 16864 14676 16437 15649 15878>,
			<21384 18086 14523 16131 15673 15650>,
			<17041 20243 19197 15993 15520 15638>,
			<13809 21716 22327 15919 15292 15694>,
			<14005 19993 22071 15969 15078 15447>,
			<14447 16728 21619 16266 14896 15019>,
			<14629 15830 21662 17403 15037 15052>,
			<14708 16044 22561 20970 16352 15761>,
			<14716 16193 23311 23654 17940 16710>,
			<14247 16098 23461 24362 19810 18475>,
			<13393 15839 23573 24737 21641 20537>,
			<13059 15351 23851 24543 21898 21089>,
			<12959 13828 24552 23511 21282 20924>,
			<12912 12673 24990 22630 20481 20490>,
			<12903 12647 22543 22220 19213 19211>,
			<12894 12662 18804 21979 17809 17449>,
			<12917 12721 17273 22074 17506 16568>,
			<13121 13045 14395 22422 17531 16019>,
			<13372 13386 12261 22682 17634 15800>,
			<13551 13531 13060 22967 18517 16178>,
			<13713 13634 14769 23477 20147 17019>,
			<13820 13807 15435 23930 21249 18128>,
			<13883 14149 15297 24299 22113 20037>,
			<13880 14457 14930 24480 22496 21178>,
			<13688 14638 14655 24038 21899 20951>,
			<13381 14806 14423 23090 20893 20507>,
			<13295 14877 14395 22182 20762 20546>,
			<13342 14893 14489 21254 21335 21253>,
			<13423 14910 14553 20407 21786 21823>,
			<13524 14922 14420 19820 21870 22637>,
			<13653 14811 14280 19289 21789 23573>,
			<13787 14454 14603 18561 20000 21905>,
			<14039 14226 14586 17237 18081 19204>,
			<14501 14057 14521 17274 18172 17912>,
			<14387 14259 14372 17548 18715 17141>,
			<15382 14277 14368 17693 17892 16540>,
			<15837 14578 14430 17901 17741 16174>,
			<16162 15466 14797 18380 17851 16470>,
			<16272 15689 15010 18965 19413 17900>,
			<15238 14891 14871 19215 20022 18317>,
			<14135 14277 14543 18962 21114 20434>,
			<12629 14320 14497 19832 24974 25245>,
			<12629 14320 14497 19832 24974 25245>,
			<12629 14320 14497 19832 24974 25245>;
	};

	qcom,pc-temp-y6-lut {
		qcom,lut-col-legend = <(-10) 0 10 25 40 50>;
		qcom,lut-row-legend = <10000 9800 9600 9400 9200 9000>,
			<8800 8600 8400 8200 8000 7800>,
			<7600 7400 7200 7000 6800 6600>,
			<6400 6200 6000 5800 5600 5400>,
			<5200 5000 4800 4600 4400 4200>,
			<4000 3800 3600 3400 3200 3000>,
			<2800 2600 2400 2200 2000 1800>,
			<1600 1400 1200 1000 900 800>,
			<700 600 500 400 300 200>,
			<100 0>;
		qcom,lut-data = <6540 5982 5452 5134 5059 5045>,
			<6479 5958 5456 5134 5059 5045>,
			<6421 5935 5457 5133 5059 5046>,
			<6367 5913 5457 5133 5059 5046>,
			<6317 5893 5456 5133 5060 5047>,
			<6274 5874 5454 5133 5060 5048>,
			<6234 5859 5448 5132 5061 5048>,
			<6200 5844 5439 5132 5062 5049>,
			<6177 5824 5436 5132 5063 5050>,
			<6158 5794 5434 5133 5064 5051>,
			<6149 5777 5433 5134 5065 5052>,
			<6162 5799 5438 5135 5067 5053>,
			<6185 5836 5445 5137 5069 5055>,
			<6174 5833 5444 5140 5071 5057>,
			<6069 5751 5432 5148 5075 5059>,
			<5990 5684 5420 5154 5078 5061>,
			<5990 5674 5409 5157 5082 5064>,
			<5991 5668 5394 5161 5086 5068>,
			<5991 5660 5383 5163 5091 5073>,
			<5985 5648 5372 5162 5097 5080>,
			<5979 5637 5360 5158 5101 5084>,
			<5976 5628 5347 5141 5088 5074>,
			<5974 5621 5333 5119 5067 5056>,
			<5974 5618 5327 5111 5059 5049>,
			<5980 5615 5324 5107 5056 5046>,
			<5989 5614 5321 5106 5055 5044>,
			<5999 5619 5319 5107 5055 5045>,
			<6011 5633 5317 5108 5057 5046>,
			<6024 5648 5318 5110 5058 5048>,
			<6038 5662 5325 5112 5061 5050>,
			<6054 5679 5334 5115 5065 5053>,
			<6074 5698 5345 5116 5069 5057>,
			<6097 5720 5360 5118 5073 5061>,
			<6120 5744 5376 5119 5073 5062>,
			<6143 5769 5395 5121 5072 5062>,
			<6168 5797 5417 5122 5070 5061>,
			<6195 5826 5439 5122 5066 5056>,
			<6225 5857 5464 5122 5060 5049>,
			<6258 5890 5493 5123 5059 5048>,
			<6294 5926 5528 5126 5062 5051>,
			<6333 5963 5567 5131 5065 5054>,
			<6377 5998 5610 5137 5066 5056>,
			<6426 6033 5659 5143 5067 5057>,
			<6480 6074 5719 5150 5064 5051>,
			<6544 6126 5788 5159 5064 5050>,
			<6576 6163 5801 5171 5072 5060>,
			<6593 6181 5833 5175 5081 5071>,
			<6650 6228 5892 5190 5092 5082>,
			<6709 6277 5958 5206 5101 5089>,
			<6771 6323 6009 5213 5096 5079>,
			<6836 6361 6061 5207 5079 5062>,
			<6906 6403 6131 5221 5080 5063>,
			<7059 6483 6233 5257 5090 5071>,
			<7649 6601 6332 5311 5114 5090>,
			<7649 6601 6332 5311 5114 5090>,
			<7649 6601 6332 5311 5114 5090>;
	};
};
